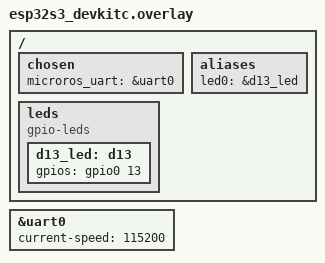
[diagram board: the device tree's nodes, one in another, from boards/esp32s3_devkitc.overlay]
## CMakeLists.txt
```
cmake_minimum_required(VERSION 3.13.1)

# Configurazione WAMR — solo variabili, NON include ancora
set(WAMR_BUILD_PLATFORM "zephyr")
set(WAMR_BUILD_INTERP 1)
set(WAMR_BUILD_LIBC_BUILTIN 1)
set(WAMR_BUILD_LIBC_WASI 0)
set(WAMR_BUILD_FAST_INTERP 0)
set(WAMR_BUILD_GLOBAL_HEAP_POOL 1)
set(WAMR_BUILD_GLOBAL_HEAP_SIZE 131072)
set(WAMR_ROOT_DIR $ENV{WAMR_ROOT} CACHE PATH "Path to WAMR root directory")

list(APPEND ZEPHYR_EXTRA_MODULES ${CMAKE_CURRENT_SOURCE_DIR}/modules/libmicroros)

find_package(Zephyr REQUIRED HINTS $ENV{ZEPHYR_BASE})

project(microros_wamr_app)

# Include WAMR DOPO find_package(Zephyr) — toolchain ARM già attivo
include(${WAMR_ROOT_DIR}/build-scripts/runtime_lib.cmake)

target_sources(app PRIVATE
    ${WAMR_RUNTIME_LIB_SOURCE}
    ${CMAKE_CURRENT_SOURCE_DIR}/src/main.c
    ${CMAKE_CURRENT_SOURCE_DIR}/src/wasm_export_native.c
)

target_link_libraries(app PUBLIC microros)

target_include_directories(app PRIVATE
    ${APP_INC_DIRS}
    ${CMAKE_CURRENT_SOURCE_DIR}/include
)
```

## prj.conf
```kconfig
CONFIG_GPIO=y
CONFIG_MICROROS=y
CONFIG_CPP=y

CONFIG_HEAP_MEM_POOL_SIZE=4096

CONFIG_MAIN_STACK_SIZE=8192
CONFIG_MAIN_THREAD_PRIORITY=3

CONFIG_NEWLIB_LIBC=y
CONFIG_NEWLIB_LIBC_NANO=n
CONFIG_PTHREAD_IPC=n
CONFIG_COMMON_LIBC_MALLOC_ARENA_SIZE=0

CONFIG_POSIX_API=y
CONFIG_POSIX_CLOCK=y

CONFIG_STDOUT_CONSOLE=y
CONFIG_LOG=n
CONFIG_SERIAL=y
CONFIG_UART_INTERRUPT_DRIVEN=y
CONFIG_UART_LINE_CTRL=y

# Stack thread WASM (deve contenere il frame dell'interprete)
CONFIG_SYSTEM_WORKQUEUE_STACK_SIZE=1024
CONFIG_FILE_SYSTEM=y
```

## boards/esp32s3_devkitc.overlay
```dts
/ {
    chosen {
        microros_uart = &uart0;
    };

    aliases {
        led0 = &d13_led;
    };

    leds {
        compatible = "gpio-leds";
        d13_led: d13 {
            gpios = <&gpio0 13 GPIO_ACTIVE_HIGH>;
        };
    };
};

&uart0 {
    status = "okay";
    current-speed = <115200>;
};
```

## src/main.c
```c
#include <zephyr/kernel.h>
#include <zephyr/device.h>
#include <zephyr/drivers/uart.h>
#include <zephyr/logging/log.h>

#include "wasm_export_native.h"
#include "service_app_wasm.h"
//#include "led_toggle_app_wasm.h"


LOG_MODULE_REGISTER(main, LOG_LEVEL_INF);

/* ── WAMR sizing ─────────────────────────────────────────────────────────── */
#define WASM_STACK_SIZE   2048
#define WASM_HEAP_SIZE    4096

/* ── Thread config ───────────────────────────────────────────────────────── */
#define WASM_THREAD_STACK_SIZE   3072
#define WASM_THREAD_PRIORITY     5

K_THREAD_STACK_DEFINE(wasm_thread_stack, WASM_THREAD_STACK_SIZE);
static struct k_thread wasm_thread_data;

/* ── Shared state passed to the thread ───────────────────────────────────── */
struct wasm_thread_ctx {
    wasm_module_inst_t instance;
    int                result;   /* populated by thread before exit */
};



/* ── Thread entry ─────────────────────────────────────────────────────────── */
static void wasm_thread_entry(void *p1, void *p2, void *p3)
{
    struct wasm_thread_ctx *ctx = (struct wasm_thread_ctx *)p1;
    ARG_UNUSED(p2);
    ARG_UNUSED(p3);

    ctx->result = 0;

    wasm_function_inst_t func =
        wasm_runtime_lookup_function(ctx->instance, "app_main");
    if (!func) {
        printk("app_main not found");
        ctx->result = -ENOENT;
        return;
    }

    wasm_exec_env_t exec_env =
        wasm_runtime_create_exec_env(ctx->instance, WASM_STACK_SIZE);
    if (!exec_env) {
        printk("Failed to create exec_env");
        ctx->result = -ENOMEM;
        return;
    }

    if (!wasm_runtime_call_wasm(exec_env, func, 0, NULL)) {
        printk("Exec error: %s",wasm_runtime_get_exception(ctx->instance));
        ctx->result = -EFAULT;
    }

    wasm_runtime_destroy_exec_env(exec_env);
}




/* ── Entry point ───────────────────────────────────────────────────────── */
void main(void)
{

    /* WAMR init */
    RuntimeInitArgs init_args = {0};
    init_args.mem_alloc_type = Alloc_With_System_Allocator;
    if (!wasm_runtime_full_init(&init_args)) {
        printk("WAMR init failed\n");
        return -ENOMEM;
    }

    /* Registra funzioni native */
    if (!register_native_functions()) {
        printk("Native registration failed\n");
        wasm_runtime_destroy();
        return -EFAULT;
    }

    /* Carica modulo WASM */
    char error_buf[128];
    wasm_module_t module = wasm_runtime_load(
        (uint8_t*) service_app_aot, service_app_aot_len,
        error_buf, sizeof(error_buf));
    if (!module) {
        printk("Load failed: %s\n", error_buf);
        wasm_runtime_destroy();
        return -EINVAL;
    }

    /* Istanzia */
    wasm_module_inst_t instance = wasm_runtime_instantiate(
        module, WASM_STACK_SIZE, WASM_HEAP_SIZE,
        error_buf, sizeof(error_buf));
    if (!instance) {
        printk("Instantiate failed: %s\n", error_buf);
        wasm_runtime_unload(module);
        wasm_runtime_destroy();
        return -EINVAL;
    }

    /* Prepara contesto e lancia thread */
    struct wasm_thread_ctx ctx = {
        .instance = instance,
        .result   = 0,
    };

    k_tid_t tid = k_thread_create(
        &wasm_thread_data,
        wasm_thread_stack, WASM_THREAD_STACK_SIZE,
        wasm_thread_entry,
        &ctx, NULL, NULL,
        WASM_THREAD_PRIORITY, 0, K_NO_WAIT);

    printk("WASM instance created, spawning thread\n");

    /* Attendi il completamento del thread */
    k_thread_join(&wasm_thread_data, K_FOREVER);

    if (ctx.result != 0) {
        //LOG_ERR("WASM thread exited with error: %d", ctx.result);
    } else {
        //LOG_INF("WASM thread completed successfully");
    }

    /* Cleanup */
    wasm_runtime_deinstantiate(instance);
    wasm_runtime_unload(module);
    wasm_runtime_destroy();

    return ctx.result;
}
```

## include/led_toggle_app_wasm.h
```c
unsigned char led_toggle_app_wasm[] = {
  0x00, 0x61, 0x73, 0x6d, 0x01, 0x00, 0x00, 0x00, 0x01, 0x04, 0x01, 0x60,
  0x00, 0x00, 0x02, 0x31, 0x02, 0x03, 0x65, 0x6e, 0x76, 0x12, 0x6d, 0x69,
  0x63, 0x72, 0x6f, 0x5f, 0x72, 0x6f, 0x73, 0x5f, 0x61, 0x70, 0x70, 0x5f,
  0x69, 0x6e, 0x69, 0x74, 0x00, 0x00, 0x03, 0x65, 0x6e, 0x76, 0x10, 0x67,
  0x72, 0x65, 0x65, 0x6e, 0x5f, 0x6c, 0x65, 0x64, 0x5f, 0x74, 0x6f, 0x67,
  0x67, 0x6c, 0x65, 0x00, 0x00, 0x03, 0x02, 0x01, 0x00, 0x04, 0x05, 0x01,
  0x70, 0x01, 0x01, 0x01, 0x05, 0x03, 0x01, 0x00, 0x01, 0x06, 0x08, 0x01,
  0x7f, 0x01, 0x41, 0x80, 0x80, 0x04, 0x0b, 0x07, 0x15, 0x02, 0x06, 0x6d,
  0x65, 0x6d, 0x6f, 0x72, 0x79, 0x02, 0x00, 0x08, 0x61, 0x70, 0x70, 0x5f,
  0x6d, 0x61, 0x69, 0x6e, 0x00, 0x02, 0x0a, 0x15, 0x01, 0x13, 0x00, 0x10,
  0x80, 0x80, 0x80, 0x80, 0x00, 0x03, 0x40, 0x10, 0x81, 0x80, 0x80, 0x80,
  0x00, 0x0c, 0x00, 0x0b, 0x0b, 0x00, 0x62, 0x04, 0x6e, 0x61, 0x6d, 0x65,
  0x00, 0x14, 0x13, 0x6c, 0x65, 0x64, 0x5f, 0x74, 0x6f, 0x67, 0x67, 0x6c,
  0x65, 0x5f, 0x61, 0x70, 0x70, 0x2e, 0x77, 0x61, 0x73, 0x6d, 0x01, 0x31,
  0x03, 0x00, 0x12, 0x6d, 0x69, 0x63, 0x72, 0x6f, 0x5f, 0x72, 0x6f, 0x73,
  0x5f, 0x61, 0x70, 0x70, 0x5f, 0x69, 0x6e, 0x69, 0x74, 0x01, 0x10, 0x67,
  0x72, 0x65, 0x65, 0x6e, 0x5f, 0x6c, 0x65, 0x64, 0x5f, 0x74, 0x6f, 0x67,
  0x67, 0x6c, 0x65, 0x02, 0x08, 0x61, 0x70, 0x70, 0x5f, 0x6d, 0x61, 0x69,
  0x6e, 0x07, 0x12, 0x01, 0x00, 0x0f, 0x5f, 0x5f, 0x73, 0x74, 0x61, 0x63,
  0x6b, 0x5f, 0x70, 0x6f, 0x69, 0x6e, 0x74, 0x65, 0x72, 0x00, 0x7f, 0x09,
  0x70, 0x72, 0x6f, 0x64, 0x75, 0x63, 0x65, 0x72, 0x73, 0x01, 0x0c, 0x70,
  0x72, 0x6f, 0x63, 0x65, 0x73, 0x73, 0x65, 0x64, 0x2d, 0x62, 0x79, 0x01,
  0x05, 0x63, 0x6c, 0x61, 0x6e, 0x67, 0x5f, 0x32, 0x32, 0x2e, 0x31, 0x2e,
  0x30, 0x2d, 0x77, 0x61, 0x73, 0x69, 0x2d, 0x73, 0x64, 0x6b, 0x20, 0x28,
  0x68, 0x74, 0x74, 0x70, 0x73, 0x3a, 0x2f, 0x2f, 0x67, 0x69, 0x74, 0x68,
  0x75, 0x62, 0x2e, 0x63, 0x6f, 0x6d, 0x2f, 0x6c, 0x6c, 0x76, 0x6d, 0x2f,
  0x6c, 0x6c, 0x76, 0x6d, 0x2d, 0x70, 0x72, 0x6f, 0x6a, 0x65, 0x63, 0x74,
  0x20, 0x34, 0x34, 0x33, 0x34, 0x64, 0x61, 0x62, 0x62, 0x36, 0x39, 0x39,
  0x31, 0x36, 0x38, 0x35, 0x36, 0x62, 0x38, 0x32, 0x34, 0x66, 0x36, 0x38,
  0x61, 0x36, 0x34, 0x62, 0x30, 0x32, 0x39, 0x63, 0x36, 0x37, 0x31, 0x37,
  0x35, 0x65, 0x35, 0x33, 0x32, 0x29, 0x00, 0x94, 0x01, 0x0f, 0x74, 0x61,
  0x72, 0x67, 0x65, 0x74, 0x5f, 0x66, 0x65, 0x61, 0x74, 0x75, 0x72, 0x65,
  0x73, 0x08, 0x2b, 0x0b, 0x62, 0x75, 0x6c, 0x6b, 0x2d, 0x6d, 0x65, 0x6d,
  0x6f, 0x72, 0x79, 0x2b, 0x0f, 0x62, 0x75, 0x6c, 0x6b, 0x2d, 0x6d, 0x65,
  0x6d, 0x6f, 0x72, 0x79, 0x2d, 0x6f, 0x70, 0x74, 0x2b, 0x16, 0x63, 0x61,
  0x6c, 0x6c, 0x2d, 0x69, 0x6e, 0x64, 0x69, 0x72, 0x65, 0x63, 0x74, 0x2d,
  0x6f, 0x76, 0x65, 0x72, 0x6c, 0x6f, 0x6e, 0x67, 0x2b, 0x0a, 0x6d, 0x75,
  0x6c, 0x74, 0x69, 0x76, 0x61, 0x6c, 0x75, 0x65, 0x2b, 0x0f, 0x6d, 0x75,
  0x74, 0x61, 0x62, 0x6c, 0x65, 0x2d, 0x67, 0x6c, 0x6f, 0x62, 0x61, 0x6c,
  0x73, 0x2b, 0x13, 0x6e, 0x6f, 0x6e, 0x74, 0x72, 0x61, 0x70, 0x70, 0x69,
  0x6e, 0x67, 0x2d, 0x66, 0x70, 0x74, 0x6f, 0x69, 0x6e, 0x74, 0x2b, 0x0f,
  0x72, 0x65, 0x66, 0x65, 0x72, 0x65, 0x6e, 0x63, 0x65, 0x2d, 0x74, 0x79,
  0x70, 0x65, 0x73, 0x2b, 0x08, 0x73, 0x69, 0x67, 0x6e, 0x2d, 0x65, 0x78,
  0x74
};
unsigned int led_toggle_app_wasm_len = 517;
```

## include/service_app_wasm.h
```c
unsigned char service_app_aot[] = {
  0x00, 0x61, 0x6f, 0x74, 0x05, 0x00, 0x00, 0x00, 0x00, 0x00, 0x00, 0x00,
  0x30, 0x00, 0x00, 0x00, 0x00, 0x00, 0x00, 0x00, 0x01, 0x00, 0x28, 0x00,
  0x01, 0x00, 0x00, 0x00, 0x00, 0x00, 0x00, 0x05, 0x00, 0x00, 0x00, 0x00,
  0x00, 0x00, 0x00, 0x00, 0x00, 0x00, 0x00, 0x00, 0x00, 0x00, 0x00, 0x00,
  0x74, 0x68, 0x75, 0x6d, 0x62, 0x76, 0x37, 0x65, 0x6d, 0x00, 0x00, 0x00,
  0x00, 0x00, 0x00, 0x00, 0x01, 0x00, 0x00, 0x00, 0xcc, 0x00, 0x00, 0x00,
  0x00, 0x00, 0x00, 0x00, 0x01, 0x00, 0x00, 0x00, 0x00, 0x00, 0x00, 0x00,
  0x00, 0x00, 0x01, 0x00, 0x01, 0x00, 0x00, 0x00, 0x01, 0x00, 0x00, 0x00,
  0x00, 0x00, 0x00, 0x00, 0x00, 0x00, 0x00, 0x00, 0x01, 0x00, 0x00, 0x00,
  0x70, 0x01, 0x00, 0x00, 0x01, 0x00, 0x00, 0x00, 0x01, 0x00, 0x00, 0x00,
  0x00, 0x00, 0x00, 0x00, 0x01, 0x00, 0x00, 0x00, 0x00, 0x00, 0x00, 0x00,
  0x00, 0x00, 0x00, 0x00, 0x00, 0x00, 0x00, 0x00, 0x01, 0x00, 0x00, 0x00,
  0x7f, 0x01, 0x00, 0x00, 0x41, 0x00, 0x00, 0x00, 0x00, 0x00, 0x01, 0x00,
  0x01, 0x00, 0x00, 0x00, 0x00, 0x00, 0x04, 0x00, 0x65, 0x6e, 0x76, 0x00,
  0x17, 0x00, 0x6d, 0x69, 0x63, 0x72, 0x6f, 0x5f, 0x72, 0x6f, 0x73, 0x5f,
  0x73, 0x65, 0x72, 0x76, 0x69, 0x63, 0x65, 0x5f, 0x69, 0x6e, 0x69, 0x74,
  0x00, 0x00, 0x00, 0x00, 0x01, 0x00, 0x00, 0x00, 0xff, 0xff, 0xff, 0xff,
  0xff, 0xff, 0xff, 0xff, 0x00, 0x00, 0x00, 0x00, 0x00, 0x00, 0x00, 0x00,
  0xff, 0xff, 0xff, 0xff, 0x00, 0x00, 0x00, 0x00, 0x00, 0x00, 0x00, 0x00,
  0xff, 0xff, 0xff, 0xff, 0x00, 0x00, 0x00, 0x00, 0x00, 0x00, 0x00, 0x00,
  0x00, 0x00, 0x00, 0x00, 0x01, 0x00, 0x00, 0x00, 0x11, 0x00, 0x2e, 0x61,
  0x6f, 0x74, 0x5f, 0x73, 0x74, 0x61, 0x63, 0x6b, 0x5f, 0x73, 0x69, 0x7a,
  0x65, 0x73, 0x00, 0x00, 0x04, 0x00, 0x00, 0x00, 0x30, 0x00, 0x00, 0x00,
  0x02, 0x00, 0x00, 0x00, 0x3c, 0x00, 0x00, 0x00, 0x00, 0x00, 0x00, 0x00,
  0x80, 0xb5, 0x82, 0xb0, 0x40, 0xf2, 0x00, 0x01, 0x01, 0xaa, 0xc0, 0xf2,
  0x00, 0x01, 0x09, 0x68, 0x51, 0x1a, 0x06, 0xd3, 0x02, 0x69, 0x91, 0x42,
  0x03, 0xd3, 0x02, 0xb0, 0xbd, 0xe8, 0x80, 0x40, 0x05, 0xe0, 0x80, 0x68,
  0x0b, 0x21, 0xff, 0xf7, 0xfe, 0xff, 0x02, 0xb0, 0x80, 0xbd, 0xc3, 0x68,
  0x00, 0x21, 0x00, 0x22, 0xff, 0xf7, 0xfe, 0xbf, 0x03, 0x00, 0x00, 0x00,
  0x10, 0x00, 0x00, 0x00, 0x00, 0x00, 0x00, 0x00, 0x00, 0x00, 0x00, 0x00,
  0x00, 0x00, 0x00, 0x00, 0x00, 0x00, 0x00, 0x00, 0x04, 0x00, 0x00, 0x00,
  0x25, 0x00, 0x00, 0x00, 0x02, 0x00, 0x00, 0x00, 0x00, 0x00, 0x00, 0x00,
  0x02, 0x00, 0x07, 0x00, 0x6d, 0x65, 0x6d, 0x6f, 0x72, 0x79, 0x00, 0x00,
  0x01, 0x00, 0x00, 0x00, 0x00, 0x00, 0x09, 0x00, 0x61, 0x70, 0x70, 0x5f,
  0x6d, 0x61, 0x69, 0x6e, 0x00, 0x00, 0x00, 0x00, 0x05, 0x00, 0x00, 0x00,
  0xb4, 0x00, 0x00, 0x00, 0x04, 0x00, 0x00, 0x00, 0x00, 0x00, 0x00, 0x00,
  0x0c, 0x00, 0x00, 0x00, 0x20, 0x00, 0x00, 0x00, 0x3c, 0x00, 0x00, 0x00,
  0x50, 0x00, 0x00, 0x00, 0x0a, 0x00, 0x2e, 0x72, 0x65, 0x6c, 0x2e, 0x74,
  0x65, 0x78, 0x74, 0x00, 0x11, 0x00, 0x2e, 0x61, 0x6f, 0x74, 0x5f, 0x73,
  0x74, 0x61, 0x63, 0x6b, 0x5f, 0x73, 0x69, 0x7a, 0x65, 0x73, 0x00, 0x00,
  0x1a, 0x00, 0x61, 0x6f, 0x74, 0x5f, 0x73, 0x65, 0x74, 0x5f, 0x65, 0x78,
  0x63, 0x65, 0x70, 0x74, 0x69, 0x6f, 0x6e, 0x5f, 0x77, 0x69, 0x74, 0x68,
  0x5f, 0x69, 0x64, 0x00, 0x12, 0x00, 0x61, 0x6f, 0x74, 0x5f, 0x69, 0x6e,
  0x76, 0x6f, 0x6b, 0x65, 0x5f, 0x6e, 0x61, 0x74, 0x69, 0x76, 0x65, 0x00,
  0x01, 0x00, 0x00, 0x00, 0x00, 0x00, 0x00, 0x00, 0x04, 0x00, 0x00, 0x00,
  0x04, 0x00, 0x00, 0x00, 0x00, 0x00, 0x00, 0x00, 0x2f, 0x00, 0x00, 0x00,
  0x01, 0x00, 0x00, 0x00, 0x0a, 0x00, 0x00, 0x00, 0x00, 0x00, 0x00, 0x00,
  0x30, 0x00, 0x00, 0x00, 0x01, 0x00, 0x00, 0x00, 0x26, 0x00, 0x00, 0x00,
  0x00, 0x00, 0x00, 0x00, 0x0a, 0x00, 0x00, 0x00, 0x02, 0x00, 0x00, 0x00,
  0x34, 0x00, 0x00, 0x00, 0x00, 0x00, 0x00, 0x00, 0x1e, 0x00, 0x00, 0x00,
  0x03, 0x00, 0x00, 0x00
};
unsigned int service_app_aot_len = 604;
```

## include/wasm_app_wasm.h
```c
unsigned char wasm_app_wasm[] = {
  0x00, 0x61, 0x73, 0x6d, 0x01, 0x00, 0x00, 0x00, 0x01, 0x04, 0x01, 0x60,
  0x00, 0x00, 0x02, 0x16, 0x01, 0x03, 0x65, 0x6e, 0x76, 0x0e, 0x6d, 0x69,
  0x63, 0x72, 0x6f, 0x5f, 0x72, 0x6f, 0x73, 0x5f, 0x69, 0x6e, 0x69, 0x74,
  0x00, 0x00, 0x03, 0x02, 0x01, 0x00, 0x04, 0x05, 0x01, 0x70, 0x01, 0x01,
  0x01, 0x05, 0x03, 0x01, 0x00, 0x01, 0x06, 0x08, 0x01, 0x7f, 0x01, 0x41,
  0x80, 0x80, 0x04, 0x0b, 0x07, 0x15, 0x02, 0x06, 0x6d, 0x65, 0x6d, 0x6f,
  0x72, 0x79, 0x02, 0x00, 0x08, 0x61, 0x70, 0x70, 0x5f, 0x6d, 0x61, 0x69,
  0x6e, 0x00, 0x01, 0x0a, 0x0a, 0x01, 0x08, 0x00, 0x10, 0x80, 0x80, 0x80,
  0x80, 0x00, 0x0b
};
unsigned int wasm_app_wasm_len = 99;
```

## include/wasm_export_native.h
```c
/*
 * src/wasm_export_native.h
 *
 * Dichiarazioni per le funzioni native (host-side) esposte al modulo WASM.
 */

#ifndef WASM_EXPORT_NATIVE_H
#define WASM_EXPORT_NATIVE_H


#include "wasm_export.h"

/* Chiamata da main.c dopo init runtime, prima del load del modulo */
bool register_native_functions(void);



#endif /* WASM_EXPORT_NATIVE_H */
```

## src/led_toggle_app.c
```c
/*
 * led_toggle.c
 *
 * Build command:
 *
 *  /opt/wasi-sdk/bin/clang --target=wasm32-unknown-unknown -nostdlib -Wl,--no-entry -Wl,--export=app_main -Wl,--allow-undefined -O2 -o led_toggle_app.wasm led_toggle_app.c
 *   xxd -i led_toggle_app.wasm > ../src/led_toggle_app_wasm.h
 *
 *
 */

/* Declare the host-provided functions as imports */

extern void green_led_toggle();
extern void micro_ros_app_init();
extern void sleep_ms(int ms);
/* ------------------------------------------------------------------ */
/*  Entry point called by the WAMR host                               */
/* ------------------------------------------------------------------ */
__attribute__((export_name("app_main")))
void app_main(void)
{
    micro_ros_app_init();
    while (1) {
        green_led_toggle();
    }
}
```

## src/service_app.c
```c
/*
 * service_app.c
 *

 * Build command:
 *
 *  /opt/wasi-sdk/bin/clang --target=wasm32-unknown-unknown -nostdlib -Wl,--no-entry -Wl,--export=app_main -Wl,--allow-undefined -O2 -o service_app.wasm service_app.c
 *   xxd -i service_app.wasm > ../src/service_app_wasm.h
 * 
 *
 */

/* Declare the host-provided functions as imports */
extern void micro_ros_service_init();
extern void sleep_ms(int ms);
/* ------------------------------------------------------------------ */
/*  Entry point called by the WAMR host                               */
/* ------------------------------------------------------------------ */
__attribute__((export_name("app_main")))
void app_main(void)
{
    micro_ros_service_init();
   
}
```

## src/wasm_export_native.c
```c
#include <zephyr/kernel.h>
#include <zephyr/drivers/gpio.h>
#include <zephyr/logging/log.h>

#include "wasm_export.h"
#include "wasm_export_native.h"

#include <rcl/rcl.h>
#include <rcl/error_handling.h>
#include <rclc/rclc.h>
#include <rclc/executor.h>
#include <rmw_microros/rmw_microros.h>
#include <std_srvs/srv/set_bool.h>
#include <microros_transports.h>

#define LED0_NODE DT_ALIAS(led0)

rcl_allocator_t allocator;
rclc_support_t  support;
rcl_node_t      node;
rcl_service_t   service;
rclc_executor_t executor;
rcl_client_t client;

LOG_MODULE_REGISTER(wasm_native, LOG_LEVEL_INF);


static std_srvs__srv__SetBool_Request  request_msg;
static std_srvs__srv__SetBool_Response response_msg;
static const struct gpio_dt_spec my_pin = GPIO_DT_SPEC_GET(DT_NODELABEL(pb8_out), gpios);

extern bool zephyr_transport_open(struct uxrCustomTransport *transport);
extern bool zephyr_transport_close(struct uxrCustomTransport *transport);
extern size_t zephyr_transport_write(struct uxrCustomTransport *transport,
                                     const uint8_t *buf, size_t len,
                                     uint8_t *err);
extern size_t zephyr_transport_read(struct uxrCustomTransport *transport,
                                    uint8_t *buf, size_t len, int timeout,
                                    uint8_t *err);

void service_callback(const void *req, void *res)
{
    std_srvs__srv__SetBool_Request  *request  = (std_srvs__srv__SetBool_Request *)  req;
    std_srvs__srv__SetBool_Response *response = (std_srvs__srv__SetBool_Response *) res;

    ARG_UNUSED(request);

    gpio_pin_toggle_dt(&my_pin);
    response->success = true;
}

static void native_micro_ros_service_init(wasm_exec_env_t exec_env)
{
    ARG_UNUSED(exec_env);

 
    gpio_pin_configure_dt(&my_pin, GPIO_OUTPUT_ACTIVE);

    rmw_uros_set_custom_transport(
        MICRO_ROS_FRAMING_REQUIRED,
        (void *) &default_params,
        zephyr_transport_open,
        zephyr_transport_close,
        zephyr_transport_write,
        zephyr_transport_read
    );

    allocator = rcl_get_default_allocator();

    printk("Pinging agent...\n");
    while (rmw_uros_ping_agent(500, 1) != RMW_RET_OK) {
        printk("retry...\n");
    }
    printk("Agent found!\n");

    if (rclc_support_init(&support, 0, NULL, &allocator) != RCL_RET_OK) {
        return;
    }

    if (rclc_node_init_default(&node, "service", "", &support) != RCL_RET_OK) {
        return;
    }

    if (rclc_service_init_default(
            &service, &node,
            ROSIDL_GET_SRV_TYPE_SUPPORT(std_srvs, srv, SetBool),
            "/green_led") != RCL_RET_OK) {
        return;
    }

    if (rclc_executor_init(&executor, &support.context, 1, &allocator) != RCL_RET_OK) {
        return;
    }

    if (rclc_executor_add_service(
            &executor, &service,
            &request_msg, &response_msg,
            service_callback) != RCL_RET_OK) {
        return;
    }

    //LOG_INF("micro-ROS service ready on /green_led");

    while (true) {
        rclc_executor_spin_some(&executor, RCL_MS_TO_NS(1000));
    }
}




static void client_callback(const void *response)
{
    std_srvs__srv__SetBool_Response *res =
        (std_srvs__srv__SetBool_Response *)response;
    printk("Response: success=%d\n", res->success);
}

static void native_micro_ros_app_init(wasm_exec_env_t exec_env)
{
    ARG_UNUSED(exec_env);

    rmw_uros_set_custom_transport(
        MICRO_ROS_FRAMING_REQUIRED,
        (void *) &default_params,
        zephyr_transport_open,
        zephyr_transport_close,
        zephyr_transport_write,
        zephyr_transport_read
    );

    allocator = rcl_get_default_allocator();

    while (rmw_uros_ping_agent(500, 1) != RMW_RET_OK) {}

    rclc_support_init(&support, 0, NULL, &allocator);
    rclc_node_init_default(&node, "zephyr_app_node", "", &support);

    rclc_client_init_default(&client, &node,
        ROSIDL_GET_SRV_TYPE_SUPPORT(std_srvs, srv, SetBool),
        "/green_led");

    rclc_executor_init(&executor, &support.context, 1, &allocator);
    rclc_executor_add_client(&executor, &client, &response_msg, client_callback);

}

static void native_green_led_toggle(wasm_exec_env_t exec_env)
{
    ARG_UNUSED(exec_env);

    std_srvs__srv__SetBool_Request req;
    std_srvs__srv__SetBool_Request__init(&req);
    req.data = true;

    int64_t sequence_number;
    rcl_send_request(&client, &req, &sequence_number);

    // Spin per ricevere la response
    rclc_executor_spin_some(&executor, RCL_MS_TO_NS(1000));
}
static void native_sleep_ms(wasm_exec_env_t exec_env, int32_t ms)
{
    (void)exec_env;
    if (ms > 0) {
        k_msleep(ms);
    }
}


static NativeSymbol native_symbols[] = {
    { "micro_ros_service_init", native_micro_ros_service_init, "()", NULL },
    { "micro_ros_app_init", native_micro_ros_app_init, "()", NULL },
    { "green_led_toggle", native_green_led_toggle, "()", NULL },
    { "sleep_ms",   native_sleep_ms,   "(i)",  NULL }
};

bool register_native_functions(void)
{
    int n = sizeof(native_symbols) / sizeof(native_symbols[0]);
    if (!wasm_runtime_register_natives("env", native_symbols, n)) {
        return false;
    }
    //LOG_INF("Registered %d native symbols", n);
    return true;
}
```
